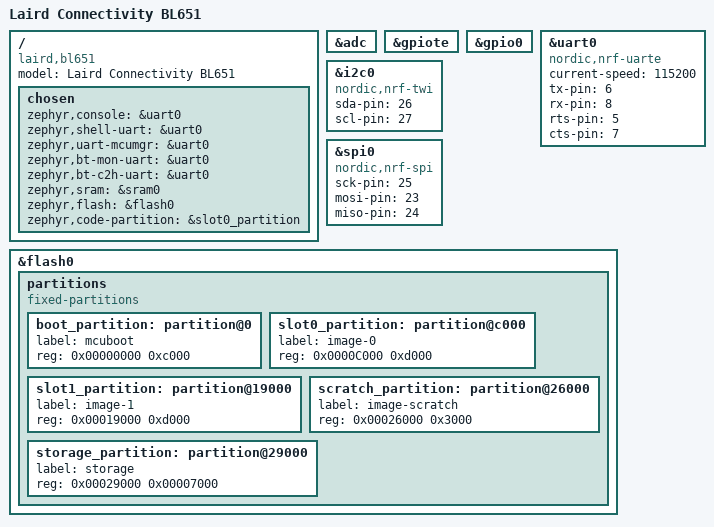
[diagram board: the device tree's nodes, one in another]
/*
 * Copyright (c) 2018 Nordic Semiconductor ASA
 * Copyright (c) 2017 Shawn Nock <shawn@monadnock.ca>
 * Copyright (c) 2017 Linaro Limited
 *
 * SPDX-License-Identifier: Apache-2.0
 */

/dts-v1/;
#include <nordic/nrf52810_qfaa.dtsi>

/ {
	model = "Laird Connectivity BL651";
	compatible = "laird,bl651";

	chosen {
		zephyr,console = &uart0;
		zephyr,shell-uart = &uart0;
		zephyr,uart-mcumgr = &uart0;
		zephyr,bt-mon-uart = &uart0;
		zephyr,bt-c2h-uart = &uart0;
		zephyr,sram = &sram0;
		zephyr,flash = &flash0;
		zephyr,code-partition = &slot0_partition;
	};
};

&adc {
	status = "okay";
};

&gpiote {
	status = "okay";
};

&gpio0 {
	status = "okay";
};

&uart0 {
	compatible = "nordic,nrf-uarte";
	status = "okay";
	current-speed = <115200>;
	tx-pin = <6>;
	rx-pin = <8>;
	rts-pin = <5>;
	cts-pin = <7>;
};

&i2c0 {
	compatible = "nordic,nrf-twi";
	status = "okay";
	sda-pin = <26>;
	scl-pin = <27>;
};

&spi0 {
	compatible = "nordic,nrf-spi";
	status = "okay";
	sck-pin = <25>;
	mosi-pin = <23>;
	miso-pin = <24>;
};

&flash0 {
	/*
	 * For more information, see:
	 * http://docs.zephyrproject.org/latest/guides/dts/index.html#flash-partitions
	 */
	partitions {
		compatible = "fixed-partitions";
		#address-cells = <1>;
		#size-cells = <1>;

		boot_partition: partition@0 {
			label = "mcuboot";
			reg = <0x00000000 0xc000>;
		};
		slot0_partition: partition@c000 {
			label = "image-0";
			reg = <0x0000C000 0xd000>;
		};
		slot1_partition: partition@19000 {
			label = "image-1";
			reg = <0x00019000 0xd000>;
		};
		scratch_partition: partition@26000 {
			label = "image-scratch";
			reg = <0x00026000 0x3000>;
		};
		storage_partition: partition@29000 {
			label = "storage";
			reg = <0x00029000 0x00007000>;
		};
	};
};
